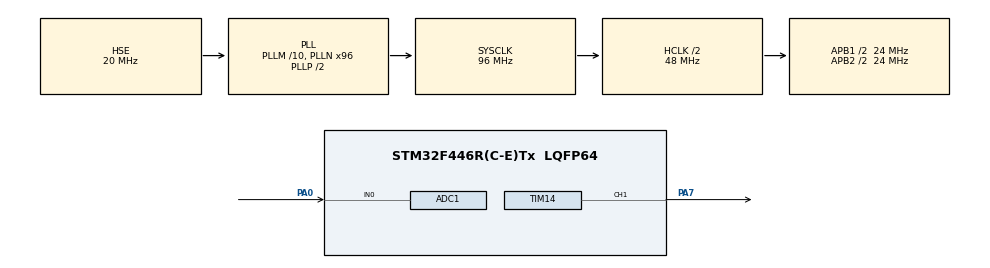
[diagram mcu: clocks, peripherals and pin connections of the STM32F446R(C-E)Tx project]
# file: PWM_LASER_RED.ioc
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ADC1.Channel-0\#ChannelRegularConversion=ADC_CHANNEL_0
ADC1.ContinuousConvMode=ENABLE
ADC1.NbrOfConversion=1
ADC1.NbrOfConversionFlag=1
ADC1.Rank-0\#ChannelRegularConversion=1
ADC1.SamplingTime-0\#ChannelRegularConversion=ADC_SAMPLETIME_480CYCLES
ADC1.ScanConvMode=DISABLE
ADC1.master=1
Mcu.Family=STM32F4
Mcu.Name=STM32F446R(C-E)Tx
Mcu.Package=LQFP64
NVIC.PriorityGroup=NVIC_PRIORITYGROUP_4
PA0-WKUP.Signal=ADCx_IN0
PA13.Mode=Serial_Wire
PA13.Signal=SYS_JTMS-SWDIO
PA14.Mode=Serial_Wire
PA14.Signal=SYS_JTCK-SWCLK
PA7.Signal=S_TIM14_CH1
PH0-OSC_IN.Mode=HSE-External-Oscillator
PH0-OSC_IN.Signal=RCC_OSC_IN
PH1-OSC_OUT.Mode=HSE-External-Oscillator
PH1-OSC_OUT.Signal=RCC_OSC_OUT
ProjectManager.HeapSize=0x200
ProjectManager.StackSize=0x400
ProjectManager.TargetToolchain=STM32CubeIDE
RCC.AHBCLKDivider=RCC_SYSCLK_DIV2
RCC.AHBFreq_Value=48000000
RCC.APB1CLKDivider=RCC_HCLK_DIV2
RCC.APB1Freq_Value=24000000
RCC.APB1TimFreq_Value=48000000
RCC.APB2CLKDivider=RCC_HCLK_DIV2
RCC.APB2Freq_Value=24000000
RCC.APB2TimFreq_Value=48000000
RCC.CortexFreq_Value=48000000
RCC.HCLKFreq_Value=48000000
RCC.HSE_VALUE=20000000
RCC.PLLM=10
RCC.PLLN=96
RCC.PLLSourceVirtual=RCC_PLLSOURCE_HSE
RCC.SYSCLKFreq_VALUE=96000000
RCC.SYSCLKSource=RCC_SYSCLKSOURCE_PLLCLK
RCC.USBFreq_Value=96000000
RCC.VCOOutputFreq_Value=192000000
SH.ADCx_IN0.0=ADC1_IN0,IN0
SH.S_TIM14_CH1.0=TIM14_CH1,PWM Generation1 CH1
TIM14.Channel=TIM_CHANNEL_1
TIM14.Period=24000-1
TIM14.Prescaler=2-1
VP_TIM14_VS_ClockSourceINT.Mode=Enable_Timer
board=custom

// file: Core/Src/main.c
/* USER CODE BEGIN Header */
/**
  ******************************************************************************
  * @file           : main.c
  * @brief          : Main program body
  ******************************************************************************
  * @attention
  *
  * Copyright (c) 2025 STMicroelectronics.
  * All rights reserved.
  *
  * This software is licensed under terms that can be found in the LICENSE file
  * in the root directory of this software component.
  * If no LICENSE file comes with this software, it is provided AS-IS.
  *
  ******************************************************************************
  */
/* USER CODE END Header */
#include "main.h"

ADC_HandleTypeDef hadc1;

TIM_HandleTypeDef htim14;

/* USER CODE BEGIN PV */
uint32_t adc1;
/* USER CODE END PV */

void SystemClock_Config(void);
static void MX_GPIO_Init(void);
static void MX_TIM14_Init(void);
static void MX_ADC1_Init(void);
/* USER CODE BEGIN PFP */
double map(float valor, float entradaMin, float entradaMax, float salidaMin, float salidaMax);
void PWM_set_Freq_DutyCycle(uint16_t freq, uint8_t duty, uint32_t tiempo);
/* USER CODE END PFP */

int main(void)
{

  /* MCU Configuration--------------------------------------------------------*/

  /* Reset of all peripherals, Initializes the Flash interface and the Systick. */
  HAL_Init();

  /* Configure the system clock */
  SystemClock_Config();

  /* Initialize all configured peripherals */
  MX_GPIO_Init();
  MX_TIM14_Init();
  MX_ADC1_Init();

  /* Infinite loop */
  /* USER CODE BEGIN WHILE */
  while (1)
  {
	  HAL_ADC_Start(&hadc1);
	  HAL_ADC_PollForConversion(&hadc1, HAL_MAX_DELAY);
	  adc1 = HAL_ADC_GetValue(&hadc1);
	  adc1 = map(adc1, 0, 4095, 0, 50);

	  PWM_set_Freq_DutyCycle(1000,adc1,0);

	  /*for(uint8_t i=1; i<=100; i++) PWM_set_Freq_DutyCycle(20000,i,20);
	  HAL_Delay(2000);
	  for(int8_t i=100; i>=0; i--) PWM_set_Freq_DutyCycle(20000,i,20);
	  HAL_Delay(2000);*/

    /* USER CODE END WHILE */

  }
}

void SystemClock_Config(void)
{
  RCC_OscInitTypeDef RCC_OscInitStruct = {0};
  RCC_ClkInitTypeDef RCC_ClkInitStruct = {0};

  /** Configure the main internal regulator output voltage
  */
  __HAL_RCC_PWR_CLK_ENABLE();
  __HAL_PWR_VOLTAGESCALING_CONFIG(PWR_REGULATOR_VOLTAGE_SCALE3);

  /** Initializes the RCC Oscillators according to the specified parameters
  * in the RCC_OscInitTypeDef structure.
  */
  RCC_OscInitStruct.OscillatorType = RCC_OSCILLATORTYPE_HSE;
  RCC_OscInitStruct.HSEState = RCC_HSE_ON;
  RCC_OscInitStruct.PLL.PLLState = RCC_PLL_ON;
  RCC_OscInitStruct.PLL.PLLSource = RCC_PLLSOURCE_HSE;
  RCC_OscInitStruct.PLL.PLLM = 10;
  RCC_OscInitStruct.PLL.PLLN = 96;
  RCC_OscInitStruct.PLL.PLLP = RCC_PLLP_DIV2;
  RCC_OscInitStruct.PLL.PLLQ = 2;
  RCC_OscInitStruct.PLL.PLLR = 2;
  if (HAL_RCC_OscConfig(&RCC_OscInitStruct) != HAL_OK)
  {
    Error_Handler();
  }

  /** Initializes the CPU, AHB and APB buses clocks
  */
  RCC_ClkInitStruct.ClockType = RCC_CLOCKTYPE_HCLK|RCC_CLOCKTYPE_SYSCLK
                              |RCC_CLOCKTYPE_PCLK1|RCC_CLOCKTYPE_PCLK2;
  RCC_ClkInitStruct.SYSCLKSource = RCC_SYSCLKSOURCE_PLLCLK;
  RCC_ClkInitStruct.AHBCLKDivider = RCC_SYSCLK_DIV2;
  RCC_ClkInitStruct.APB1CLKDivider = RCC_HCLK_DIV2;
  RCC_ClkInitStruct.APB2CLKDivider = RCC_HCLK_DIV2;

  if (HAL_RCC_ClockConfig(&RCC_ClkInitStruct, FLASH_LATENCY_1) != HAL_OK)
  {
    Error_Handler();
  }
}

static void MX_ADC1_Init(void)
{

  ADC_ChannelConfTypeDef sConfig = {0};

  /** Configure the global features of the ADC (Clock, Resolution, Data Alignment and number of conversion)
  */
  hadc1.Instance = ADC1;
  hadc1.Init.ClockPrescaler = ADC_CLOCK_SYNC_PCLK_DIV2;
  hadc1.Init.Resolution = ADC_RESOLUTION_12B;
  hadc1.Init.ScanConvMode = DISABLE;
  hadc1.Init.ContinuousConvMode = ENABLE;
  hadc1.Init.DiscontinuousConvMode = DISABLE;
  hadc1.Init.ExternalTrigConvEdge = ADC_EXTERNALTRIGCONVEDGE_NONE;
  hadc1.Init.ExternalTrigConv = ADC_SOFTWARE_START;
  hadc1.Init.DataAlign = ADC_DATAALIGN_RIGHT;
  hadc1.Init.NbrOfConversion = 1;
  hadc1.Init.DMAContinuousRequests = DISABLE;
  hadc1.Init.EOCSelection = ADC_EOC_SINGLE_CONV;
  if (HAL_ADC_Init(&hadc1) != HAL_OK)
  {
    Error_Handler();
  }

  /** Configure for the selected ADC regular channel its corresponding rank in the sequencer and its sample time.
  */
  sConfig.Channel = ADC_CHANNEL_0;
  sConfig.Rank = 1;
  sConfig.SamplingTime = ADC_SAMPLETIME_480CYCLES;
  if (HAL_ADC_ConfigChannel(&hadc1, &sConfig) != HAL_OK)
  {
    Error_Handler();
  }

}

static void MX_TIM14_Init(void)
{

  TIM_OC_InitTypeDef sConfigOC = {0};

  htim14.Instance = TIM14;
  htim14.Init.Prescaler = 2-1;
  htim14.Init.CounterMode = TIM_COUNTERMODE_UP;
  htim14.Init.Period = 24000-1;
  htim14.Init.ClockDivision = TIM_CLOCKDIVISION_DIV1;
  htim14.Init.AutoReloadPreload = TIM_AUTORELOAD_PRELOAD_DISABLE;
  if (HAL_TIM_Base_Init(&htim14) != HAL_OK)
  {
    Error_Handler();
  }
  if (HAL_TIM_PWM_Init(&htim14) != HAL_OK)
  {
    Error_Handler();
  }
  sConfigOC.OCMode = TIM_OCMODE_PWM1;
  sConfigOC.Pulse = 0;
  sConfigOC.OCPolarity = TIM_OCPOLARITY_HIGH;
  sConfigOC.OCFastMode = TIM_OCFAST_DISABLE;
  if (HAL_TIM_PWM_ConfigChannel(&htim14, &sConfigOC, TIM_CHANNEL_1) != HAL_OK)
  {
    Error_Handler();
  }
  HAL_TIM_MspPostInit(&htim14);

}

static void MX_GPIO_Init(void)
{

  /* GPIO Ports Clock Enable */
  __HAL_RCC_GPIOH_CLK_ENABLE();
  __HAL_RCC_GPIOA_CLK_ENABLE();

}

/* USER CODE BEGIN 4 */
//////////////////////// Function map/////////////////////////////////////////////////////////////
double map(float valor, float entradaMin, float entradaMax, float salidaMin, float salidaMax){
	   return ((((valor-entradaMin)*(salidaMax-salidaMin))/(entradaMax-entradaMin))+salidaMin);}

void PWM_set_Freq_DutyCycle(uint16_t freq, uint8_t duty, uint32_t tiempo){
	uint16_t valor_CCR;

	if(duty > 100) duty = 100;
	freq = HAL_RCC_GetHCLKFreq()/(freq*(htim14.Instance->PSC + 1));//le sumo +1 porque aqui no es la formaula normal de (psc+1)x(ARR+1) sino es mi formula
    HAL_TIM_PWM_Start(&htim14, TIM_CHANNEL_1);
	__HAL_TIM_SET_AUTORELOAD(&htim14,freq);//Si quiero cambiar la frecuencia modifico: __HAL_TIM_SET_AUTORELOAD(&htim15, frecuencia que quiero)
	valor_CCR = (__HAL_TIM_GET_AUTORELOAD(&htim14)+1)*duty/100;//__HAL_TIM_GET_AUTORELOAD(&htim15): esto es el valor de 10-1 osea 9, por eso le sumo 1 para volver a tener 10, y por 0.5 ya que quiero 50% del duty cycle
    __HAL_TIM_SET_COMPARE(&htim14, TIM_CHANNEL_1, valor_CCR);
    HAL_Delay(tiempo);
    //HAL_TIM_PWM_Stop(&htim14, TIM_CHANNEL_1);
}

/* USER CODE END 4 */

void Error_Handler(void)
{
  __disable_irq();
  while (1)
  {
  }
}
